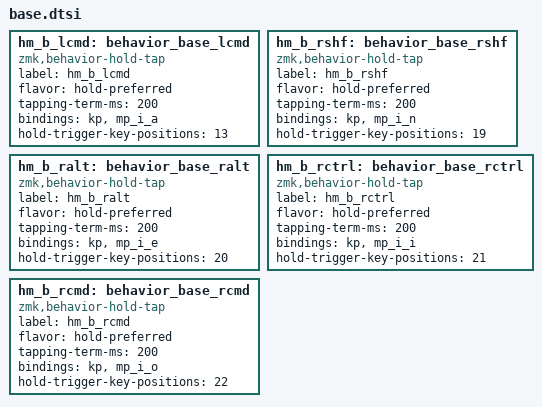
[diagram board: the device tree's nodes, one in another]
hm_b_lcmd: behavior_base_lcmd {
    compatible = "zmk,behavior-hold-tap";
    label = "hm_b_lcmd";
    #binding-cells = <2>;
    flavor = "hold-preferred";
    tapping-term-ms = <200>;
    bindings = <&kp>, <&mp_i_a>;
    hold-trigger-key-positions = <13>;
};

hm_b_rshf: behavior_base_rshf {
    compatible = "zmk,behavior-hold-tap";
    label = "hm_b_rshf";
    #binding-cells = <2>;
    flavor = "hold-preferred";
    tapping-term-ms = <200>;
    bindings = <&kp>, <&mp_i_n>;
    hold-trigger-key-positions = <19>;
};

hm_b_ralt: behavior_base_ralt {
    compatible = "zmk,behavior-hold-tap";
    label = "hm_b_ralt";
    #binding-cells = <2>;
    flavor = "hold-preferred";
    tapping-term-ms = <200>;
    bindings = <&kp>, <&mp_i_e>;
    hold-trigger-key-positions = <20>;
};

hm_b_rctrl: behavior_base_rctrl {
    compatible = "zmk,behavior-hold-tap";
    label = "hm_b_rctrl";
    #binding-cells = <2>;
    flavor = "hold-preferred";
    tapping-term-ms = <200>;
    bindings = <&kp>, <&mp_i_i>;
    hold-trigger-key-positions = <21>;
};

hm_b_rcmd: behavior_base_rcmd {
    compatible = "zmk,behavior-hold-tap";
    label = "hm_b_rcmd";
    #binding-cells = <2>;
    flavor = "hold-preferred";
    tapping-term-ms = <200>;
    bindings = <&kp>, <&mp_i_o>;
    hold-trigger-key-positions = <22>;
};
